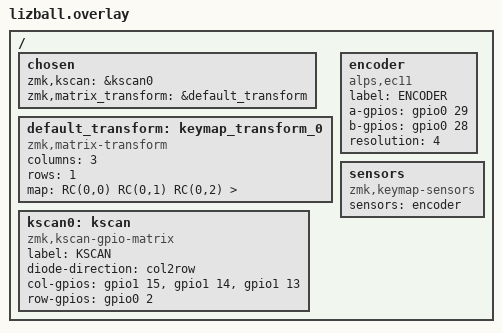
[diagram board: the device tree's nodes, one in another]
#include <dt-bindings/zmk/matrix_transform.h>

/ {
    chosen {
        zmk,kscan = &kscan0;
        zmk,matrix_transform = &default_transform;
    };

    default_transform: keymap_transform_0 {
        compatible = "zmk,matrix-transform";
        columns = <3>;
        rows = <1>;
        map = 
            RC(0,0) RC(0,1) RC(0,2)
        >;
    };

    kscan0: kscan {
        compatible = "zmk,kscan-gpio-matrix";
        label = "KSCAN";
        diode-direction = "col2row";

        col-gpios
            = <&gpio1 15 GPIO_ACTIVE_HIGH>
            , <&gpio1 14 GPIO_ACTIVE_HIGH>
            , <&gpio1 13 GPIO_ACTIVE_HIGH>
            ;

        row-gpios
            = <&gpio0 2 (GPIO_ACTIVE_HIGH | GPIO_PULL_DOWN)>
            ;
    };

    encoder: encoder {
        compatible = "alps,ec11";
        label = "ENCODER";
        a-gpios = <&gpio0 29 (GPIO_ACTIVE_HIGH | GPIO_PULL_UP)>;
        b-gpios = <&gpio0 28 (GPIO_ACTIVE_HIGH | GPIO_PULL_UP)>;
        resolution = <4>;
    };

    sensors {
        compatible = "zmk,keymap-sensors";
        sensors = <&encoder>;
    };
};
